AUTOSAR XML (schema 4-0-3)
package /Svc_IoHwAb/CompuMethods
  compu method IoHwAb_Cm_EdgeEnum: 1=IOHWAB_RISING_EDGE (IoHwAb_RisingEdge), 2=IOHWAB_FALLING_EDGE (IoHwAb_FallingEdge), 3=IOHWAB_BOTH_EDGES (IoHwAb_BothEdges)
package /Svc_IoHwAb/ImplementationDataTypes
  19 x impl type:
    IoHwAb_OcuReturnType: category=VALUE, base-type=uint8
    IoHwAb_LevelType: category=VALUE, base-type=uint8, compu {0=IOHWAB_LOW (IoHwAb_Low), 1=IOHWAB_HIGH (IoHwAb_High)}
    IoHwAb_OcuValueType: category=VALUE, base-type=uint16
    IoHwAb_IcuEdgeNumberType: category=VALUE, base-type=uint32
    IoHwAb_PwmPeriodType: category=VALUE, base-type=uint32
    IoHwAb_GptValueType: category=VALUE, base-type=uint32
    IoHwAb_IcuIndexType: category=VALUE, base-type=uint16
    IoHwAb_ValueType: category=VALUE, base-type=uint16
    IoHwAb_LengthType: category=VALUE, base-type=uint8
    IoHwAb_IndexType: category=VALUE, base-type=uint16
    IoHwAb_IcuValueType: category=VALUE, base-type=uint16
    IoHwAb_IcuStateType: category=VALUE, base-type=uint8, compu {0=IOHWAB_IDLE (IoHwAb_Idle), 1=IOHWAB_ACTIVE (IoHwAb_Active)}
    IoHwAb_BoolType: category=VALUE, base-type=uint8, compu {0=IOHWAB_FALSE (IoHwAb_False), 1=IOHWAB_TRUE (IoHwAb_True)}
    IoHwAb_PwmEdgeType: category=VALUE, base-type=uint8, compu-method=IoHwAb_Cm_EdgeEnum
    IoHwAb_ThresholdType: category=VALUE, base-type=uint8
    IoHwAb_OcuPinStateType: category=VALUE, base-type=uint8
    IoHwAb_IcuActivationType: category=VALUE, base-type=uint8, compu-method=IoHwAb_Cm_EdgeEnum
    IoHwAb_OcuPinActionType: category=VALUE, base-type=uint8
    IoHwAb_IcuDutyCycleType: category=STRUCTURE
      element ActiveTime: implementation-data-type=IoHwAb_IcuValueType
      element PeriodTime: implementation-data-type=IoHwAb_IcuValueType
package /Svc_IoHwAb/ClientServerInterfaces
  7 x client server interface, all with is-service=true:
    IoHwAb_If_McuSpecific
      operation ControlIBE: possible-error=IoHwAb_If_McuSpecific/E_NOT_SUPPORTED
        arg PortGroup: type=IoHwAb_IndexType, direction=IN, server-argument-impl-policy=USE-ARGUMENT-TYPE
        arg PinConfig: type=IoHwAb_IndexType, direction=IN, server-argument-impl-policy=USE-ARGUMENT-TYPE
        arg Level: type=IoHwAb_LevelType, direction=IN, server-argument-impl-policy=USE-ARGUMENT-TYPE
      error E_NOT_SUPPORTED: error-code=12
    IoHwAb_If_DigDir
      6 x operation:
        ReadDirect
          arg Level: type=IoHwAb_LevelType, direction=OUT, server-argument-impl-policy=USE-ARGUMENT-TYPE
        WriteDirect
          arg Level: type=IoHwAb_LevelType, direction=IN, server-argument-impl-policy=USE-ARGUMENT-TYPE
        SetToInput
        SetToOutput
        IsInput
          arg blResult: type=IoHwAb_BoolType, direction=OUT, server-argument-impl-policy=USE-ARGUMENT-TYPE
        IsOutput
          arg blResult: type=IoHwAb_BoolType, direction=OUT, server-argument-impl-policy=USE-ARGUMENT-TYPE
    IoHwAb_If_AnaInDir
      operation ReadDirect: possible-error=[IoHwAb_If_AnaInDir/E_BUSY, E_WRONG_LENGTH, E_SETUP_BUFFER_FAIL]
        arg Value: type=IoHwAb_ValueType, direction=OUT, server-argument-impl-policy=USE-ARGUMENT-TYPE
        arg AnaInDirLength: type=IoHwAb_LengthType, direction=IN, server-argument-impl-policy=USE-ARGUMENT-TYPE
      error E_BUSY: error-code=4
      error E_WRONG_LENGTH: error-code=5
      error E_SETUP_BUFFER_FAIL: error-code=6
    IoHwAb_If_AnaIn
      4 x operation:
        Read
          arg Value: type=IoHwAb_ValueType, direction=OUT, server-argument-impl-policy=USE-ARGUMENT-TYPE
        ReadDirect: possible-error=IoHwAb_If_AnaIn/E_BUSY
          arg Value: type=IoHwAb_ValueType, direction=OUT, server-argument-impl-policy=USE-ARGUMENT-TYPE
        Freeze
        Unfreeze
      error E_BUSY: error-code=7
    IoHwAb_If_Icu
      18 x operation:
        SetActivationCondition: possible-error=IoHwAb_If_Icu/E_NOT_SUPPORTED
          arg Activation: type=IoHwAb_IcuActivationType, direction=IN, server-argument-impl-policy=USE-ARGUMENT-TYPE
        DisableNotification: possible-error=IoHwAb_If_Icu/E_NOT_SUPPORTED
        EnableNotification: possible-error=IoHwAb_If_Icu/E_NOT_SUPPORTED
        GetInputState: possible-error=IoHwAb_If_Icu/E_NOT_SUPPORTED
          arg State: type=IoHwAb_IcuStateType, direction=OUT, server-argument-impl-policy=USE-ARGUMENT-TYPE
        StartTimestamp: possible-error=IoHwAb_If_Icu/E_NOT_SUPPORTED
          arg BufPtr: type=IoHwAb_IcuValueType, direction=OUT, server-argument-impl-policy=USE-ARGUMENT-TYPE
          arg BufSize: type=uint16, direction=IN, server-argument-impl-policy=USE-ARGUMENT-TYPE
          arg NotiItv: type=uint16, direction=IN, server-argument-impl-policy=USE-ARGUMENT-TYPE
        StopTimestamp: possible-error=IoHwAb_If_Icu/E_NOT_SUPPORTED
        GetTimestampIndex: possible-error=IoHwAb_If_Icu/E_NOT_SUPPORTED
          arg TimestampIdx: type=IoHwAb_IcuIndexType, direction=OUT, server-argument-impl-policy=USE-ARGUMENT-TYPE
        ResetEdgeCount: possible-error=IoHwAb_If_Icu/E_NOT_SUPPORTED
        EnableEdgeCount: possible-error=IoHwAb_If_Icu/E_NOT_SUPPORTED
        DisableEdgeCount: possible-error=IoHwAb_If_Icu/E_NOT_SUPPORTED
        GetEdgeNumbers: possible-error=IoHwAb_If_Icu/E_NOT_SUPPORTED
          arg Num: type=IoHwAb_IcuEdgeNumberType, direction=OUT, server-argument-impl-policy=USE-ARGUMENT-TYPE
        EnableEdgeDetection: possible-error=IoHwAb_If_Icu/E_NOT_SUPPORTED
        DisableEdgeDetection: possible-error=IoHwAb_If_Icu/E_NOT_SUPPORTED
        StartSignalMeasurement: possible-error=IoHwAb_If_Icu/E_NOT_SUPPORTED
        StopSignalMeasurement: possible-error=IoHwAb_If_Icu/E_NOT_SUPPORTED
        GetTimeElapsed: possible-error=IoHwAb_If_Icu/E_NOT_SUPPORTED
          arg Time: type=IoHwAb_IcuValueType, direction=OUT, server-argument-impl-policy=USE-ARGUMENT-TYPE
        GetDutyCycleValues: possible-error=IoHwAb_If_Icu/E_NOT_SUPPORTED
          arg DutyCycle: type=IoHwAb_IcuDutyCycleType, direction=OUT, server-argument-impl-policy=USE-ARGUMENT-TYPE
        Notification
      error E_NOT_SUPPORTED: error-code=9
    IoHwAb_If_Gpt
      7 x operation:
        StartTimer: possible-error=IoHwAb_If_Gpt/E_NOT_SUPPORTED
          arg Value: type=IoHwAb_GptValueType, direction=IN, server-argument-impl-policy=USE-ARGUMENT-TYPE
        StopTimer: possible-error=IoHwAb_If_Gpt/E_NOT_SUPPORTED
        GetTimeElapsed: possible-error=IoHwAb_If_Gpt/E_NOT_SUPPORTED
          arg Value: type=IoHwAb_GptValueType, direction=OUT, server-argument-impl-policy=USE-ARGUMENT-TYPE
        GetTimeRemaining: possible-error=IoHwAb_If_Gpt/E_NOT_SUPPORTED
          arg Value: type=IoHwAb_GptValueType, direction=OUT, server-argument-impl-policy=USE-ARGUMENT-TYPE
        DisableNotification: possible-error=IoHwAb_If_Gpt/E_NOT_SUPPORTED
        EnableNotification: possible-error=IoHwAb_If_Gpt/E_NOT_SUPPORTED
        Notification
      error E_NOT_SUPPORTED: error-code=10
    IoHwAb_If_Pwm
      6 x operation, all with possible-error=IoHwAb_If_Pwm/E_NOT_SUPPORTED:
        SetDutyCycle
          arg Duty: type=uint16, direction=IN, server-argument-impl-policy=USE-ARGUMENT-TYPE
        SetPeriodAndDuty
          arg Period: type=IoHwAb_PwmPeriodType, direction=IN, server-argument-impl-policy=USE-ARGUMENT-TYPE
          arg Duty: type=uint16, direction=IN, server-argument-impl-policy=USE-ARGUMENT-TYPE
        SetOutputToIdle
        GetOutputState
          arg Level: type=IoHwAb_LevelType, direction=OUT, server-argument-impl-policy=USE-ARGUMENT-TYPE
        DisableNotification
        EnableNotification
          arg NotificationEdge: type=IoHwAb_PwmEdgeType, direction=IN, server-argument-impl-policy=USE-ARGUMENT-TYPE
      error E_NOT_SUPPORTED: error-code=11
package /Svc_IoHwAb/EcuAbstractionSwComponentTypes
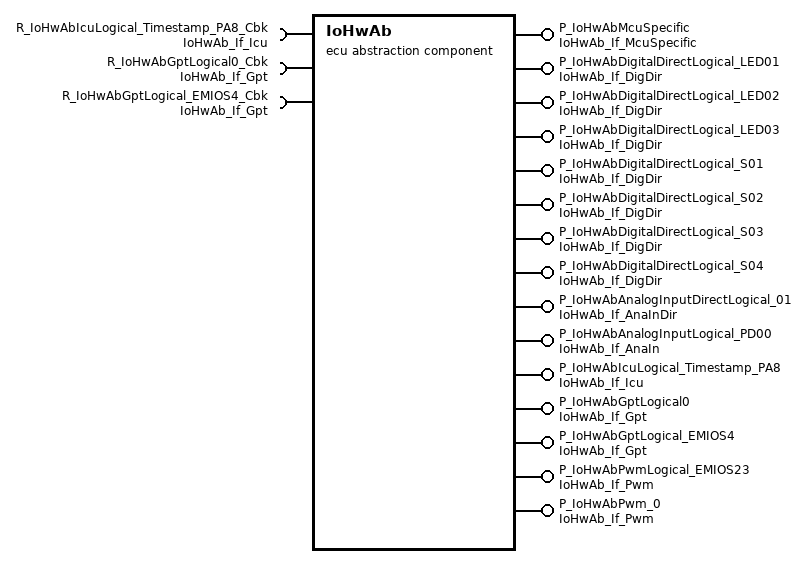
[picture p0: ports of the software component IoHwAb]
  ecu abstraction sw component type IoHwAb
    11 x provide port:
      P_IoHwAbMcuSpecific: server-com-spec{operation=ControlIBE, queue-length=1}, provided-interface=IoHwAb_If_McuSpecific
      P_IoHwAbDigitalDirectLogical_LED01: provided-interface=IoHwAb_If_DigDir
        provided-com-specs:
          operation=IoHwAb_If_DigDir/ReadDirect, queue-length=1
          operation=WriteDirect, queue-length=1
          operation=SetToInput, queue-length=1
          operation=SetToOutput, queue-length=1
          operation=IsInput, queue-length=1
          operation=IsOutput, queue-length=1
      P_IoHwAbDigitalDirectLogical_LED02: provided-interface=IoHwAb_If_DigDir
        provided-com-specs:
          operation=IoHwAb_If_DigDir/ReadDirect, queue-length=1
          operation=WriteDirect, queue-length=1
          operation=SetToInput, queue-length=1
          operation=SetToOutput, queue-length=1
          operation=IsInput, queue-length=1
          operation=IsOutput, queue-length=1
      P_IoHwAbDigitalDirectLogical_LED03: provided-interface=IoHwAb_If_DigDir
        provided-com-specs:
          operation=IoHwAb_If_DigDir/ReadDirect, queue-length=1
          operation=WriteDirect, queue-length=1
          operation=SetToInput, queue-length=1
          operation=SetToOutput, queue-length=1
          operation=IsInput, queue-length=1
          operation=IsOutput, queue-length=1
      P_IoHwAbDigitalDirectLogical_S01: provided-interface=IoHwAb_If_DigDir
        provided-com-specs:
          operation=IoHwAb_If_DigDir/ReadDirect, queue-length=1
          operation=WriteDirect, queue-length=1
          operation=SetToInput, queue-length=1
          operation=SetToOutput, queue-length=1
          operation=IsInput, queue-length=1
          operation=IsOutput, queue-length=1
      P_IoHwAbDigitalDirectLogical_S02: provided-interface=IoHwAb_If_DigDir
        provided-com-specs:
          operation=IoHwAb_If_DigDir/ReadDirect, queue-length=1
          operation=WriteDirect, queue-length=1
          operation=SetToInput, queue-length=1
          operation=SetToOutput, queue-length=1
          operation=IsInput, queue-length=1
          operation=IsOutput, queue-length=1
      P_IoHwAbDigitalDirectLogical_S03: provided-interface=IoHwAb_If_DigDir
        provided-com-specs:
          operation=IoHwAb_If_DigDir/ReadDirect, queue-length=1
          operation=WriteDirect, queue-length=1
          operation=SetToInput, queue-length=1
          operation=SetToOutput, queue-length=1
          operation=IsInput, queue-length=1
          operation=IsOutput, queue-length=1
      P_IoHwAbDigitalDirectLogical_S04: provided-interface=IoHwAb_If_DigDir
        provided-com-specs:
          operation=IoHwAb_If_DigDir/ReadDirect, queue-length=1
          operation=WriteDirect, queue-length=1
          operation=SetToInput, queue-length=1
          operation=SetToOutput, queue-length=1
          operation=IsInput, queue-length=1
          operation=IsOutput, queue-length=1
      P_IoHwAbAnalogInputDirectLogical_01: server-com-spec{operation=IoHwAb_If_AnaInDir/ReadDirect, queue-length=1}, provided-interface=IoHwAb_If_AnaInDir
      P_IoHwAbAnalogInputLogical_PD00: provided-interface=IoHwAb_If_AnaIn
        provided-com-specs:
          operation=Read, queue-length=1
          operation=IoHwAb_If_AnaIn/ReadDirect, queue-length=1
          operation=Freeze, queue-length=1
          operation=Unfreeze, queue-length=1
      P_IoHwAbIcuLogical_Timestamp_PA8: provided-interface=IoHwAb_If_Icu
        provided-com-specs:
          operation=SetActivationCondition, queue-length=1
          operation=IoHwAb_If_Icu/DisableNotification, queue-length=1
          operation=IoHwAb_If_Icu/EnableNotification, queue-length=1
          operation=GetInputState, queue-length=1
          operation=StartTimestamp, queue-length=1
          operation=StopTimestamp, queue-length=1
          operation=GetTimestampIndex, queue-length=1
          operation=ResetEdgeCount, queue-length=1
          operation=EnableEdgeCount, queue-length=1
          operation=DisableEdgeCount, queue-length=1
          operation=GetEdgeNumbers, queue-length=1
          operation=EnableEdgeDetection, queue-length=1
          operation=DisableEdgeDetection, queue-length=1
          operation=StartSignalMeasurement, queue-length=1
          operation=StopSignalMeasurement, queue-length=1
          operation=IoHwAb_If_Icu/GetTimeElapsed, queue-length=1
          operation=GetDutyCycleValues, queue-length=1
    require port R_IoHwAbIcuLogical_Timestamp_PA8_Cbk: client-com-spec=IoHwAb_If_Icu/Notification, required-interface=IoHwAb_If_Icu
    provide port P_IoHwAbGptLogical0: provided-interface=IoHwAb_If_Gpt
      provided-com-specs:
        operation=StartTimer, queue-length=1
        operation=StopTimer, queue-length=1
        operation=IoHwAb_If_Gpt/GetTimeElapsed, queue-length=1
        operation=GetTimeRemaining, queue-length=1
        operation=IoHwAb_If_Gpt/DisableNotification, queue-length=1
        operation=IoHwAb_If_Gpt/EnableNotification, queue-length=1
    require port R_IoHwAbGptLogical0_Cbk: client-com-spec=IoHwAb_If_Gpt/Notification, required-interface=IoHwAb_If_Gpt
    provide port P_IoHwAbGptLogical_EMIOS4: provided-interface=IoHwAb_If_Gpt
      provided-com-specs:
        operation=StartTimer, queue-length=1
        operation=StopTimer, queue-length=1
        operation=IoHwAb_If_Gpt/GetTimeElapsed, queue-length=1
        operation=GetTimeRemaining, queue-length=1
        operation=IoHwAb_If_Gpt/DisableNotification, queue-length=1
        operation=IoHwAb_If_Gpt/EnableNotification, queue-length=1
    require port R_IoHwAbGptLogical_EMIOS4_Cbk: client-com-spec=IoHwAb_If_Gpt/Notification, required-interface=IoHwAb_If_Gpt
    provide port P_IoHwAbPwmLogical_EMIOS23: provided-interface=IoHwAb_If_Pwm
      provided-com-specs:
        operation=SetDutyCycle, queue-length=1
        operation=SetPeriodAndDuty, queue-length=1
        operation=SetOutputToIdle, queue-length=1
        operation=GetOutputState, queue-length=1
        operation=IoHwAb_If_Pwm/DisableNotification, queue-length=1
        operation=IoHwAb_If_Pwm/EnableNotification, queue-length=1
    provide port P_IoHwAbPwm_0: provided-interface=IoHwAb_If_Pwm
      provided-com-specs:
        operation=SetDutyCycle, queue-length=1
        operation=SetPeriodAndDuty, queue-length=1
        operation=SetOutputToIdle, queue-length=1
        operation=GetOutputState, queue-length=1
        operation=IoHwAb_If_Pwm/DisableNotification, queue-length=1
        operation=IoHwAb_If_Pwm/EnableNotification, queue-length=1
    behavior IB_IoHwAb
      89 x operation invoked event:
        IoHwAb_Ev_IoHwAbMcuSpecific_ControlIBE: start-on-event=IoHwAb_Re_McuSpecific_ControlIBE, operation=P_IoHwAbMcuSpecific.ControlIBE
        IoHwAb_Ev_IoHwAbDigitalDirectLogical_LED01_ReadDirect: start-on-event=IoHwAb_Re_DigDir_ReadDirect, operation=P_IoHwAbDigitalDirectLogical_LED01.ReadDirect
        IoHwAb_Ev_IoHwAbDigitalDirectLogical_LED01_WriteDirect: start-on-event=IoHwAb_Re_DigDir_WriteDirect, operation=P_IoHwAbDigitalDirectLogical_LED01.WriteDirect
        IoHwAb_Ev_IoHwAbDigitalDirectLogical_LED01_SetToInput: start-on-event=IoHwAb_Re_DigDir_SetToInput, operation=P_IoHwAbDigitalDirectLogical_LED01.SetToInput
        IoHwAb_Ev_IoHwAbDigitalDirectLogical_LED01_SetToOutput: start-on-event=IoHwAb_Re_DigDir_SetToOutput, operation=P_IoHwAbDigitalDirectLogical_LED01.SetToOutput
        IoHwAb_Ev_IoHwAbDigitalDirectLogical_LED01_IsInput: start-on-event=IoHwAb_Re_DigDir_IsInput, operation=P_IoHwAbDigitalDirectLogical_LED01.IsInput
        IoHwAb_Ev_IoHwAbDigitalDirectLogical_LED01_IsOutput: start-on-event=IoHwAb_Re_DigDir_IsOutput, operation=P_IoHwAbDigitalDirectLogical_LED01.IsOutput
        IoHwAb_Ev_IoHwAbDigitalDirectLogical_LED02_ReadDirect: start-on-event=IoHwAb_Re_DigDir_ReadDirect, operation=P_IoHwAbDigitalDirectLogical_LED02.ReadDirect
        IoHwAb_Ev_IoHwAbDigitalDirectLogical_LED02_WriteDirect: start-on-event=IoHwAb_Re_DigDir_WriteDirect, operation=P_IoHwAbDigitalDirectLogical_LED02.WriteDirect
        IoHwAb_Ev_IoHwAbDigitalDirectLogical_LED02_SetToInput: start-on-event=IoHwAb_Re_DigDir_SetToInput, operation=P_IoHwAbDigitalDirectLogical_LED02.SetToInput
        IoHwAb_Ev_IoHwAbDigitalDirectLogical_LED02_SetToOutput: start-on-event=IoHwAb_Re_DigDir_SetToOutput, operation=P_IoHwAbDigitalDirectLogical_LED02.SetToOutput
        IoHwAb_Ev_IoHwAbDigitalDirectLogical_LED02_IsInput: start-on-event=IoHwAb_Re_DigDir_IsInput, operation=P_IoHwAbDigitalDirectLogical_LED02.IsInput
        IoHwAb_Ev_IoHwAbDigitalDirectLogical_LED02_IsOutput: start-on-event=IoHwAb_Re_DigDir_IsOutput, operation=P_IoHwAbDigitalDirectLogical_LED02.IsOutput
        IoHwAb_Ev_IoHwAbDigitalDirectLogical_LED03_ReadDirect: start-on-event=IoHwAb_Re_DigDir_ReadDirect, operation=P_IoHwAbDigitalDirectLogical_LED03.ReadDirect
        IoHwAb_Ev_IoHwAbDigitalDirectLogical_LED03_WriteDirect: start-on-event=IoHwAb_Re_DigDir_WriteDirect, operation=P_IoHwAbDigitalDirectLogical_LED03.WriteDirect
        IoHwAb_Ev_IoHwAbDigitalDirectLogical_LED03_SetToInput: start-on-event=IoHwAb_Re_DigDir_SetToInput, operation=P_IoHwAbDigitalDirectLogical_LED03.SetToInput
        IoHwAb_Ev_IoHwAbDigitalDirectLogical_LED03_SetToOutput: start-on-event=IoHwAb_Re_DigDir_SetToOutput, operation=P_IoHwAbDigitalDirectLogical_LED03.SetToOutput
        IoHwAb_Ev_IoHwAbDigitalDirectLogical_LED03_IsInput: start-on-event=IoHwAb_Re_DigDir_IsInput, operation=P_IoHwAbDigitalDirectLogical_LED03.IsInput
        IoHwAb_Ev_IoHwAbDigitalDirectLogical_LED03_IsOutput: start-on-event=IoHwAb_Re_DigDir_IsOutput, operation=P_IoHwAbDigitalDirectLogical_LED03.IsOutput
        IoHwAb_Ev_IoHwAbDigitalDirectLogical_S01_ReadDirect: start-on-event=IoHwAb_Re_DigDir_ReadDirect, operation=P_IoHwAbDigitalDirectLogical_S01.ReadDirect
        IoHwAb_Ev_IoHwAbDigitalDirectLogical_S01_WriteDirect: start-on-event=IoHwAb_Re_DigDir_WriteDirect, operation=P_IoHwAbDigitalDirectLogical_S01.WriteDirect
        IoHwAb_Ev_IoHwAbDigitalDirectLogical_S01_SetToInput: start-on-event=IoHwAb_Re_DigDir_SetToInput, operation=P_IoHwAbDigitalDirectLogical_S01.SetToInput
        IoHwAb_Ev_IoHwAbDigitalDirectLogical_S01_SetToOutput: start-on-event=IoHwAb_Re_DigDir_SetToOutput, operation=P_IoHwAbDigitalDirectLogical_S01.SetToOutput
        IoHwAb_Ev_IoHwAbDigitalDirectLogical_S01_IsInput: start-on-event=IoHwAb_Re_DigDir_IsInput, operation=P_IoHwAbDigitalDirectLogical_S01.IsInput
        IoHwAb_Ev_IoHwAbDigitalDirectLogical_S01_IsOutput: start-on-event=IoHwAb_Re_DigDir_IsOutput, operation=P_IoHwAbDigitalDirectLogical_S01.IsOutput
        IoHwAb_Ev_IoHwAbDigitalDirectLogical_S02_ReadDirect: start-on-event=IoHwAb_Re_DigDir_ReadDirect, operation=P_IoHwAbDigitalDirectLogical_S02.ReadDirect
        IoHwAb_Ev_IoHwAbDigitalDirectLogical_S02_WriteDirect: start-on-event=IoHwAb_Re_DigDir_WriteDirect, operation=P_IoHwAbDigitalDirectLogical_S02.WriteDirect
        IoHwAb_Ev_IoHwAbDigitalDirectLogical_S02_SetToInput: start-on-event=IoHwAb_Re_DigDir_SetToInput, operation=P_IoHwAbDigitalDirectLogical_S02.SetToInput
        IoHwAb_Ev_IoHwAbDigitalDirectLogical_S02_SetToOutput: start-on-event=IoHwAb_Re_DigDir_SetToOutput, operation=P_IoHwAbDigitalDirectLogical_S02.SetToOutput
        IoHwAb_Ev_IoHwAbDigitalDirectLogical_S02_IsInput: start-on-event=IoHwAb_Re_DigDir_IsInput, operation=P_IoHwAbDigitalDirectLogical_S02.IsInput
        IoHwAb_Ev_IoHwAbDigitalDirectLogical_S02_IsOutput: start-on-event=IoHwAb_Re_DigDir_IsOutput, operation=P_IoHwAbDigitalDirectLogical_S02.IsOutput
        IoHwAb_Ev_IoHwAbDigitalDirectLogical_S03_ReadDirect: start-on-event=IoHwAb_Re_DigDir_ReadDirect, operation=P_IoHwAbDigitalDirectLogical_S03.ReadDirect
        IoHwAb_Ev_IoHwAbDigitalDirectLogical_S03_WriteDirect: start-on-event=IoHwAb_Re_DigDir_WriteDirect, operation=P_IoHwAbDigitalDirectLogical_S03.WriteDirect
        IoHwAb_Ev_IoHwAbDigitalDirectLogical_S03_SetToInput: start-on-event=IoHwAb_Re_DigDir_SetToInput, operation=P_IoHwAbDigitalDirectLogical_S03.SetToInput
        IoHwAb_Ev_IoHwAbDigitalDirectLogical_S03_SetToOutput: start-on-event=IoHwAb_Re_DigDir_SetToOutput, operation=P_IoHwAbDigitalDirectLogical_S03.SetToOutput
        IoHwAb_Ev_IoHwAbDigitalDirectLogical_S03_IsInput: start-on-event=IoHwAb_Re_DigDir_IsInput, operation=P_IoHwAbDigitalDirectLogical_S03.IsInput
        IoHwAb_Ev_IoHwAbDigitalDirectLogical_S03_IsOutput: start-on-event=IoHwAb_Re_DigDir_IsOutput, operation=P_IoHwAbDigitalDirectLogical_S03.IsOutput
        IoHwAb_Ev_IoHwAbDigitalDirectLogical_S04_ReadDirect: start-on-event=IoHwAb_Re_DigDir_ReadDirect, operation=P_IoHwAbDigitalDirectLogical_S04.ReadDirect
        IoHwAb_Ev_IoHwAbDigitalDirectLogical_S04_WriteDirect: start-on-event=IoHwAb_Re_DigDir_WriteDirect, operation=P_IoHwAbDigitalDirectLogical_S04.WriteDirect
        IoHwAb_Ev_IoHwAbDigitalDirectLogical_S04_SetToInput: start-on-event=IoHwAb_Re_DigDir_SetToInput, operation=P_IoHwAbDigitalDirectLogical_S04.SetToInput
        IoHwAb_Ev_IoHwAbDigitalDirectLogical_S04_SetToOutput: start-on-event=IoHwAb_Re_DigDir_SetToOutput, operation=P_IoHwAbDigitalDirectLogical_S04.SetToOutput
        IoHwAb_Ev_IoHwAbDigitalDirectLogical_S04_IsInput: start-on-event=IoHwAb_Re_DigDir_IsInput, operation=P_IoHwAbDigitalDirectLogical_S04.IsInput
        IoHwAb_Ev_IoHwAbDigitalDirectLogical_S04_IsOutput: start-on-event=IoHwAb_Re_DigDir_IsOutput, operation=P_IoHwAbDigitalDirectLogical_S04.IsOutput
        IoHwAb_Ev_IoHwAbAnalogInputDirectLogical_01_ReadDirect: start-on-event=IoHwAb_Re_AnaInDir_ReadDirect, operation=P_IoHwAbAnalogInputDirectLogical_01.ReadDirect
        IoHwAb_Ev_IoHwAbAnalogInputLogical_PD00_Read: start-on-event=IoHwAb_Re_AnaIn_Read, operation=P_IoHwAbAnalogInputLogical_PD00.Read
        IoHwAb_Ev_IoHwAbAnalogInputLogical_PD00_ReadDirect: start-on-event=IoHwAb_Re_AnaIn_ReadDirect, operation=P_IoHwAbAnalogInputLogical_PD00.ReadDirect
        IoHwAb_Ev_IoHwAbAnalogInputLogical_PD00_Freeze: start-on-event=IoHwAb_Re_AnaIn_Freeze, operation=P_IoHwAbAnalogInputLogical_PD00.Freeze
        IoHwAb_Ev_IoHwAbAnalogInputLogical_PD00_Unfreeze: start-on-event=IoHwAb_Re_AnaIn_Unfreeze, operation=P_IoHwAbAnalogInputLogical_PD00.Unfreeze
        IoHwAb_Ev_IoHwAbIcuLogical_Timestamp_PA8_SetActivationCondition: start-on-event=IoHwAb_Re_Icu_SetActivationCondition, operation=P_IoHwAbIcuLogical_Timestamp_PA8.SetActivationCondition
        IoHwAb_Ev_IoHwAbIcuLogical_Timestamp_PA8_DisableNotification: start-on-event=IoHwAb_Re_Icu_DisableNotification, operation=P_IoHwAbIcuLogical_Timestamp_PA8.DisableNotification
        IoHwAb_Ev_IoHwAbIcuLogical_Timestamp_PA8_EnableNotification: start-on-event=IoHwAb_Re_Icu_EnableNotification, operation=P_IoHwAbIcuLogical_Timestamp_PA8.EnableNotification
        IoHwAb_Ev_IoHwAbIcuLogical_Timestamp_PA8_GetInputState: start-on-event=IoHwAb_Re_Icu_GetInputState, operation=P_IoHwAbIcuLogical_Timestamp_PA8.GetInputState
        IoHwAb_Ev_IoHwAbIcuLogical_Timestamp_PA8_StartTimestamp: start-on-event=IoHwAb_Re_Icu_StartTimestamp, operation=P_IoHwAbIcuLogical_Timestamp_PA8.StartTimestamp
        IoHwAb_Ev_IoHwAbIcuLogical_Timestamp_PA8_StopTimestamp: start-on-event=IoHwAb_Re_Icu_StopTimestamp, operation=P_IoHwAbIcuLogical_Timestamp_PA8.StopTimestamp
        IoHwAb_Ev_IoHwAbIcuLogical_Timestamp_PA8_GetTimestampIndex: start-on-event=IoHwAb_Re_Icu_GetTimestampIndex, operation=P_IoHwAbIcuLogical_Timestamp_PA8.GetTimestampIndex
        IoHwAb_Ev_IoHwAbIcuLogical_Timestamp_PA8_ResetEdgeCount: start-on-event=IoHwAb_Re_Icu_ResetEdgeCount, operation=P_IoHwAbIcuLogical_Timestamp_PA8.ResetEdgeCount
        IoHwAb_Ev_IoHwAbIcuLogical_Timestamp_PA8_EnableEdgeCount: start-on-event=IoHwAb_Re_Icu_EnableEdgeCount, operation=P_IoHwAbIcuLogical_Timestamp_PA8.EnableEdgeCount
        IoHwAb_Ev_IoHwAbIcuLogical_Timestamp_PA8_DisableEdgeCount: start-on-event=IoHwAb_Re_Icu_DisableEdgeCount, operation=P_IoHwAbIcuLogical_Timestamp_PA8.DisableEdgeCount
        IoHwAb_Ev_IoHwAbIcuLogical_Timestamp_PA8_GetEdgeNumbers: start-on-event=IoHwAb_Re_Icu_GetEdgeNumbers, operation=P_IoHwAbIcuLogical_Timestamp_PA8.GetEdgeNumbers
        IoHwAb_Ev_IoHwAbIcuLogical_Timestamp_PA8_EnableEdgeDetection: start-on-event=IoHwAb_Re_Icu_EnableEdgeDetection, operation=P_IoHwAbIcuLogical_Timestamp_PA8.EnableEdgeDetection
        IoHwAb_Ev_IoHwAbIcuLogical_Timestamp_PA8_DisableEdgeDetection: start-on-event=IoHwAb_Re_Icu_DisableEdgeDetection, operation=P_IoHwAbIcuLogical_Timestamp_PA8.DisableEdgeDetection
        IoHwAb_Ev_IoHwAbIcuLogical_Timestamp_PA8_StartSignalMeasurement: start-on-event=IoHwAb_Re_Icu_StartSignalMeasurement, operation=P_IoHwAbIcuLogical_Timestamp_PA8.StartSignalMeasurement
        IoHwAb_Ev_IoHwAbIcuLogical_Timestamp_PA8_StopSignalMeasurement: start-on-event=IoHwAb_Re_Icu_StopSignalMeasurement, operation=P_IoHwAbIcuLogical_Timestamp_PA8.StopSignalMeasurement
        IoHwAb_Ev_IoHwAbIcuLogical_Timestamp_PA8_GetTimeElapsed: start-on-event=IoHwAb_Re_Icu_GetTimeElapsed, operation=P_IoHwAbIcuLogical_Timestamp_PA8.GetTimeElapsed
        IoHwAb_Ev_IoHwAbIcuLogical_Timestamp_PA8_GetDutyCycleValues: start-on-event=IoHwAb_Re_Icu_GetDutyCycleValues, operation=P_IoHwAbIcuLogical_Timestamp_PA8.GetDutyCycleValues
        IoHwAb_Ev_IoHwAbGptLogical0_StartTimer: start-on-event=IoHwAb_Re_Gpt_StartTimer, operation=P_IoHwAbGptLogical0.StartTimer
        IoHwAb_Ev_IoHwAbGptLogical0_StopTimer: start-on-event=IoHwAb_Re_Gpt_StopTimer, operation=P_IoHwAbGptLogical0.StopTimer
        IoHwAb_Ev_IoHwAbGptLogical0_GetTimeElapsed: start-on-event=IoHwAb_Re_Gpt_GetTimeElapsed, operation=P_IoHwAbGptLogical0.GetTimeElapsed
        IoHwAb_Ev_IoHwAbGptLogical0_GetTimeRemaining: start-on-event=IoHwAb_Re_Gpt_GetTimeRemaining, operation=P_IoHwAbGptLogical0.GetTimeRemaining
        IoHwAb_Ev_IoHwAbGptLogical0_DisableNotification: start-on-event=IoHwAb_Re_Gpt_DisableNotification, operation=P_IoHwAbGptLogical0.DisableNotification
        IoHwAb_Ev_IoHwAbGptLogical0_EnableNotification: start-on-event=IoHwAb_Re_Gpt_EnableNotification, operation=P_IoHwAbGptLogical0.EnableNotification
        IoHwAb_Ev_IoHwAbGptLogical_EMIOS4_StartTimer: start-on-event=IoHwAb_Re_Gpt_StartTimer, operation=P_IoHwAbGptLogical_EMIOS4.StartTimer
        IoHwAb_Ev_IoHwAbGptLogical_EMIOS4_StopTimer: start-on-event=IoHwAb_Re_Gpt_StopTimer, operation=P_IoHwAbGptLogical_EMIOS4.StopTimer
        IoHwAb_Ev_IoHwAbGptLogical_EMIOS4_GetTimeElapsed: start-on-event=IoHwAb_Re_Gpt_GetTimeElapsed, operation=P_IoHwAbGptLogical_EMIOS4.GetTimeElapsed
        IoHwAb_Ev_IoHwAbGptLogical_EMIOS4_GetTimeRemaining: start-on-event=IoHwAb_Re_Gpt_GetTimeRemaining, operation=P_IoHwAbGptLogical_EMIOS4.GetTimeRemaining
        IoHwAb_Ev_IoHwAbGptLogical_EMIOS4_DisableNotification: start-on-event=IoHwAb_Re_Gpt_DisableNotification, operation=P_IoHwAbGptLogical_EMIOS4.DisableNotification
        IoHwAb_Ev_IoHwAbGptLogical_EMIOS4_EnableNotification: start-on-event=IoHwAb_Re_Gpt_EnableNotification, operation=P_IoHwAbGptLogical_EMIOS4.EnableNotification
        IoHwAb_Ev_IoHwAbPwmLogical_EMIOS23_SetDutyCycle: start-on-event=IoHwAb_Re_Pwm_SetDutyCycle, operation=P_IoHwAbPwmLogical_EMIOS23.SetDutyCycle
        IoHwAb_Ev_IoHwAbPwmLogical_EMIOS23_SetPeriodAndDuty: start-on-event=IoHwAb_Re_Pwm_SetPeriodAndDuty, operation=P_IoHwAbPwmLogical_EMIOS23.SetPeriodAndDuty
        IoHwAb_Ev_IoHwAbPwmLogical_EMIOS23_SetOutputToIdle: start-on-event=IoHwAb_Re_Pwm_SetOutputToIdle, operation=P_IoHwAbPwmLogical_EMIOS23.SetOutputToIdle
        IoHwAb_Ev_IoHwAbPwmLogical_EMIOS23_GetOutputState: start-on-event=IoHwAb_Re_Pwm_GetOutputState, operation=P_IoHwAbPwmLogical_EMIOS23.GetOutputState
        IoHwAb_Ev_IoHwAbPwmLogical_EMIOS23_DisableNotification: start-on-event=IoHwAb_Re_Pwm_DisableNotification, operation=P_IoHwAbPwmLogical_EMIOS23.DisableNotification
        IoHwAb_Ev_IoHwAbPwmLogical_EMIOS23_EnableNotification: start-on-event=IoHwAb_Re_Pwm_EnableNotification, operation=P_IoHwAbPwmLogical_EMIOS23.EnableNotification
        IoHwAb_Ev_IoHwAbPwm_0_SetDutyCycle: start-on-event=IoHwAb_Re_Pwm_SetDutyCycle, operation=P_IoHwAbPwm_0.SetDutyCycle
        IoHwAb_Ev_IoHwAbPwm_0_SetPeriodAndDuty: start-on-event=IoHwAb_Re_Pwm_SetPeriodAndDuty, operation=P_IoHwAbPwm_0.SetPeriodAndDuty
        IoHwAb_Ev_IoHwAbPwm_0_SetOutputToIdle: start-on-event=IoHwAb_Re_Pwm_SetOutputToIdle, operation=P_IoHwAbPwm_0.SetOutputToIdle
        IoHwAb_Ev_IoHwAbPwm_0_GetOutputState: start-on-event=IoHwAb_Re_Pwm_GetOutputState, operation=P_IoHwAbPwm_0.GetOutputState
        IoHwAb_Ev_IoHwAbPwm_0_DisableNotification: start-on-event=IoHwAb_Re_Pwm_DisableNotification, operation=P_IoHwAbPwm_0.DisableNotification
        IoHwAb_Ev_IoHwAbPwm_0_EnableNotification: start-on-event=IoHwAb_Re_Pwm_EnableNotification, operation=P_IoHwAbPwm_0.EnableNotification
      port-api-options:
        {enable-take-address=false, indirect-api=false, port-defined-argument-value{value=0, value-type=IoHwAb_IndexType}, port=P_IoHwAbDigitalDirectLogical_LED01}
        {enable-take-address=false, indirect-api=false, port-defined-argument-value{value=1, value-type=IoHwAb_IndexType}, port=P_IoHwAbDigitalDirectLogical_LED02}
        {enable-take-address=false, indirect-api=false, port-defined-argument-value{value=2, value-type=IoHwAb_IndexType}, port=P_IoHwAbDigitalDirectLogical_LED03}
        {enable-take-address=false, indirect-api=false, port-defined-argument-value{value=3, value-type=IoHwAb_IndexType}, port=P_IoHwAbDigitalDirectLogical_S01}
        {enable-take-address=false, indirect-api=false, port-defined-argument-value{value=4, value-type=IoHwAb_IndexType}, port=P_IoHwAbDigitalDirectLogical_S02}
        {enable-take-address=false, indirect-api=false, port-defined-argument-value{value=5, value-type=IoHwAb_IndexType}, port=P_IoHwAbDigitalDirectLogical_S03}
        {enable-take-address=false, indirect-api=false, port-defined-argument-value{value=6, value-type=IoHwAb_IndexType}, port=P_IoHwAbDigitalDirectLogical_S04}
        {enable-take-address=false, indirect-api=false, port-defined-argument-value{value=0, value-type=IoHwAb_IndexType}, port=P_IoHwAbAnalogInputDirectLogical_01}
        {enable-take-address=false, indirect-api=false, port-defined-argument-value{value=0, value-type=IoHwAb_IndexType}, port=P_IoHwAbAnalogInputLogical_PD00}
        {enable-take-address=false, indirect-api=false, port-defined-argument-value{value=0, value-type=IoHwAb_IndexType}, port=P_IoHwAbIcuLogical_Timestamp_PA8}
        {enable-take-address=false, indirect-api=false, port-defined-argument-value{value=0, value-type=IoHwAb_IndexType}, port=P_IoHwAbGptLogical0}
        {enable-take-address=false, indirect-api=false, port-defined-argument-value{value=1, value-type=IoHwAb_IndexType}, port=P_IoHwAbGptLogical_EMIOS4}
        {enable-take-address=false, indirect-api=false, port-defined-argument-value{value=0, value-type=IoHwAb_IndexType}, port=P_IoHwAbPwmLogical_EMIOS23}
        {enable-take-address=false, indirect-api=false, port-defined-argument-value{value=1, value-type=IoHwAb_IndexType}, port=P_IoHwAbPwm_0}
      44 x runnable, all with can-be-invoked-concurrently=true:
        IoHwAb_Re_McuSpecific_ControlIBE: symbol=IoHwAb_McuSpecificControlIBE
        IoHwAb_Re_DigDir_ReadDirect: symbol=IoHwAb_DigDirReadDirect
        IoHwAb_Re_DigDir_WriteDirect: symbol=IoHwAb_DigDirWriteDirect
        IoHwAb_Re_DigDir_SetToInput: symbol=IoHwAb_DigDirSetToInput
        IoHwAb_Re_DigDir_SetToOutput: symbol=IoHwAb_DigDirSetToOutput
        IoHwAb_Re_DigDir_IsInput: symbol=IoHwAb_DigDirIsInput
        IoHwAb_Re_DigDir_IsOutput: symbol=IoHwAb_DigDirIsOutput
        IoHwAb_Re_AnaInDir_ReadDirect: symbol=IoHwAb_AnaInDirReadDirect
        IoHwAb_Re_AnaIn_Read: symbol=IoHwAb_AnaInRead
        IoHwAb_Re_AnaIn_ReadDirect: symbol=IoHwAb_AnaInReadDirect
        IoHwAb_Re_AnaIn_Freeze: symbol=IoHwAb_AnaInFreeze
        IoHwAb_Re_AnaIn_Unfreeze: symbol=IoHwAb_AnaInUnfreeze
        IoHwAb_Re_Icu_SetActivationCondition: symbol=IoHwAb_IcuSetActivationCondition
        IoHwAb_Re_Icu_DisableNotification: symbol=IoHwAb_IcuDisableNotification
        IoHwAb_Re_Icu_EnableNotification: symbol=IoHwAb_IcuEnableNotification
        IoHwAb_Re_Icu_GetInputState: symbol=IoHwAb_IcuGetInputState
        IoHwAb_Re_Icu_StartTimestamp: symbol=IoHwAb_IcuStartTimestamp
        IoHwAb_Re_Icu_StopTimestamp: symbol=IoHwAb_IcuStopTimestamp
        IoHwAb_Re_Icu_GetTimestampIndex: symbol=IoHwAb_IcuGetTimestampIndex
        IoHwAb_Re_Icu_ResetEdgeCount: symbol=IoHwAb_IcuResetEdgeCount
        IoHwAb_Re_Icu_EnableEdgeCount: symbol=IoHwAb_IcuEnableEdgeCount
        IoHwAb_Re_Icu_DisableEdgeCount: symbol=IoHwAb_IcuDisableEdgeCount
        IoHwAb_Re_Icu_GetEdgeNumbers: symbol=IoHwAb_IcuGetEdgeNumbers
        IoHwAb_Re_Icu_EnableEdgeDetection: symbol=IoHwAb_IcuEnableEdgeDetection
        IoHwAb_Re_Icu_DisableEdgeDetection: symbol=IoHwAb_IcuDisableEdgeDetection
        IoHwAb_Re_Icu_StartSignalMeasurement: symbol=IoHwAb_IcuStartSignalMeasurement
        IoHwAb_Re_Icu_StopSignalMeasurement: symbol=IoHwAb_IcuStopSignalMeasurement
        IoHwAb_Re_Icu_GetTimeElapsed: symbol=IoHwAb_IcuGetTimeElapsed
        IoHwAb_Re_Icu_GetDutyCycleValues: symbol=IoHwAb_IcuGetDutyCycleValues
        IoHwAb_Re_Icu_IcuTimestampMeasurement_0_Cbk_Cbk: symbol=IcuTimestampMeasurement_0_Cbk
          sync call IoHwAb_Cp_Icu_IoHwAbIcuLogical_Timestamp_PA8_Cbk: operation=R_IoHwAbIcuLogical_Timestamp_PA8_Cbk.Notification, timeout=0.0
        IoHwAb_Re_Gpt_StartTimer: symbol=IoHwAb_GptStartTimer
        IoHwAb_Re_Gpt_StopTimer: symbol=IoHwAb_GptStopTimer
        IoHwAb_Re_Gpt_GetTimeElapsed: symbol=IoHwAb_GptGetTimeElapsed
        IoHwAb_Re_Gpt_GetTimeRemaining: symbol=IoHwAb_GptGetTimeRemaining
        IoHwAb_Re_Gpt_DisableNotification: symbol=IoHwAb_GptDisableNotification
        IoHwAb_Re_Gpt_EnableNotification: symbol=IoHwAb_GptEnableNotification
        IoHwAb_Re_Gpt_GptChannelConfiguration_Dummy_Cbk_Cbk: symbol=GptChannelConfiguration_Dummy_Cbk
          sync call IoHwAb_Cp_Gpt_IoHwAbGptLogical0_Cbk: operation=R_IoHwAbGptLogical0_Cbk.Notification, timeout=0.0
        IoHwAb_Re_Gpt_GptChannelConfiguration_IoHwAbTest_Cbk_Cbk: symbol=GptChannelConfiguration_IoHwAbTest_Cbk
          sync call IoHwAb_Cp_Gpt_IoHwAbGptLogical_EMIOS4_Cbk: operation=R_IoHwAbGptLogical_EMIOS4_Cbk.Notification, timeout=0.0
        IoHwAb_Re_Pwm_SetDutyCycle: symbol=IoHwAb_PwmSetDutyCycle
        IoHwAb_Re_Pwm_SetPeriodAndDuty: symbol=IoHwAb_PwmSetPeriodAndDuty
        IoHwAb_Re_Pwm_SetOutputToIdle: symbol=IoHwAb_PwmSetOutputToIdle
        IoHwAb_Re_Pwm_GetOutputState: symbol=IoHwAb_PwmGetOutputState
        IoHwAb_Re_Pwm_DisableNotification: symbol=IoHwAb_PwmDisableNotification
        IoHwAb_Re_Pwm_EnableNotification: symbol=IoHwAb_PwmEnableNotification
  swc implementation SwcImplementation_IoHwAb: swc-bsw-mapping=SwcBswMapping_IoHwAb, behavior=IB_IoHwAb
